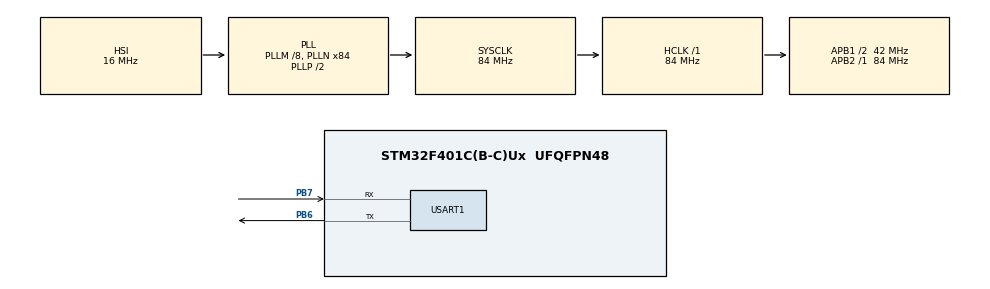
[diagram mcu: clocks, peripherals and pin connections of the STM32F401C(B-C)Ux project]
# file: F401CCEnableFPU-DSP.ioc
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Mcu.Family=STM32F4
Mcu.Name=STM32F401C(B-C)Ux
Mcu.Package=UFQFPN48
NVIC.PriorityGroup=NVIC_PRIORITYGROUP_4
PA13.Mode=Serial_Wire
PA13.Signal=SYS_JTMS-SWDIO
PA14.Mode=Serial_Wire
PA14.Signal=SYS_JTCK-SWCLK
PB6.Mode=Asynchronous
PB6.Signal=USART1_TX
PB7.Mode=Asynchronous
PB7.Signal=USART1_RX
ProjectManager.HeapSize=0x200
ProjectManager.StackSize=0x400
ProjectManager.TargetToolchain=SW4STM32
RCC.48MHZClocksFreq_Value=42000000
RCC.AHBFreq_Value=84000000
RCC.APB1CLKDivider=RCC_HCLK_DIV2
RCC.APB1Freq_Value=42000000
RCC.APB1TimFreq_Value=84000000
RCC.APB2Freq_Value=84000000
RCC.APB2TimFreq_Value=84000000
RCC.CortexFreq_Value=84000000
RCC.HCLKFreq_Value=84000000
RCC.HSE_VALUE=25000000
RCC.HSI_VALUE=16000000
RCC.LSE_VALUE=32768
RCC.PLLM=8
RCC.PLLN=84
RCC.SYSCLKFreq_VALUE=84000000
RCC.SYSCLKSource=RCC_SYSCLKSOURCE_PLLCLK
RCC.VCOOutputFreq_Value=168000000
USART1.VirtualMode=VM_ASYNC
board=custom

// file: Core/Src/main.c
/* USER CODE BEGIN Header */
/**
  ******************************************************************************
  * @file           : main.c
  * @brief          : Main program body
  ******************************************************************************
  * @attention
  *
  * Copyright (c) 2022 STMicroelectronics.
  * All rights reserved.
  *
  * This software is licensed under terms that can be found in the LICENSE file
  * in the root directory of this software component.
  * If no LICENSE file comes with this software, it is provided AS-IS.
  *
  ******************************************************************************
  */
/* USER CODE END Header */
#pragma clang diagnostic push
#pragma ide diagnostic ignored "EndlessLoop"
#include "main.h"
#include "usart.h"
#include "gpio.h"

/* USER CODE BEGIN Includes */
#include "use_dwt.h"
#include "math.h"

#ifdef ARM_MATH_CM4
#include "arm_math.h"
#endif
/* USER CODE END Includes */

void SystemClock_Config(void);

int main(void)
{

  /* MCU Configuration--------------------------------------------------------*/

  /* Reset of all peripherals, Initializes the Flash interface and the Systick. */
  HAL_Init();

  /* Configure the system clock */
  SystemClock_Config();

  /* Initialize all configured peripherals */
  MX_GPIO_Init();
  MX_USART1_UART_Init();
  /* USER CODE BEGIN 2 */
  DWT_Init();
  volatile float res;
  volatile float a = 0.5569f, b = 0.3772f;
  volatile uint32_t before, time;
  /* USER CODE END 2 */

  /* Infinite loop */
  /* USER CODE BEGIN WHILE */
  while (1)
  {
#ifdef _USING_ARM_MATH
      float f_tmp[] = {a, b, 0.0f};
      q31_t q_tmp[3];
      arm_float_to_q31(f_tmp, q_tmp, 2);
#endif
#ifdef _USING_IQ_MATH
      _iq aa = _IQ(a);
      _iq bb = _IQ(b);
      volatile _iq rr = 0;
#endif

      before = DWT_TS_GET();
      for (int i = 0; i < __MAX_LOOP_COUNT; ++i) {
#ifdef _ENABLE_TEST_FLOAT
#ifdef _USING_ARM_MATH
        arm_mult_q31(q_tmp, q_tmp + 1, q_tmp + 2, 1);
#elif _USING_IQ_MATH
        rr = _IQmpy(aa, bb);
#else
        res = a * b;
#endif
#endif

#ifdef _ENABLE_TEST_DSP
#ifndef _USING_FIX_POINT

#ifdef _USING_ARM_MATH
          res = arm_cos_f32(a) + arm_sin_f32(b);
#else
          res = cos(a) + sin(b);
#endif // _USING_ARM_MATH
#else
#ifdef _USING_ARM_MATH
          q_tmp[2] = arm_cos_q31(q_tmp[0]) + arm_sin_q31(q_tmp[1]);
#elif _USING_IQ_MATH
          rr = _IQcos(aa) + _IQcos(bb);
#endif // _USING_ARM_MATH

#endif // _USING_FIX_POINT
#endif // ENABLE_TEST_DSP
      }
      time = DWT_TS_GET() - before;
#ifdef _USING_ARM_MATH
      arm_q31_to_float(q_tmp + 2, f_tmp, 1);
      res = f_tmp[0];
#endif
#ifdef _USING_IQ_MATH
      rr = _IQtoF(rr);
#endif
      printf("Calc res = %f, CPU Cycle = %d\n", res, time);
      HAL_Delay(500);
    /* USER CODE END WHILE */

  }
}

void SystemClock_Config(void)
{
  RCC_OscInitTypeDef RCC_OscInitStruct = {0};
  RCC_ClkInitTypeDef RCC_ClkInitStruct = {0};

  /** Configure the main internal regulator output voltage
  */
  __HAL_RCC_PWR_CLK_ENABLE();
  __HAL_PWR_VOLTAGESCALING_CONFIG(PWR_REGULATOR_VOLTAGE_SCALE2);
  /** Initializes the RCC Oscillators according to the specified parameters
  * in the RCC_OscInitTypeDef structure.
  */
  RCC_OscInitStruct.OscillatorType = RCC_OSCILLATORTYPE_HSI;
  RCC_OscInitStruct.HSIState = RCC_HSI_ON;
  RCC_OscInitStruct.HSICalibrationValue = RCC_HSICALIBRATION_DEFAULT;
  RCC_OscInitStruct.PLL.PLLState = RCC_PLL_ON;
  RCC_OscInitStruct.PLL.PLLSource = RCC_PLLSOURCE_HSI;
  RCC_OscInitStruct.PLL.PLLM = 8;
  RCC_OscInitStruct.PLL.PLLN = 84;
  RCC_OscInitStruct.PLL.PLLP = RCC_PLLP_DIV2;
  RCC_OscInitStruct.PLL.PLLQ = 4;
  if (HAL_RCC_OscConfig(&RCC_OscInitStruct) != HAL_OK)
  {
    Error_Handler();
  }
  /** Initializes the CPU, AHB and APB buses clocks
  */
  RCC_ClkInitStruct.ClockType = RCC_CLOCKTYPE_HCLK|RCC_CLOCKTYPE_SYSCLK
                              |RCC_CLOCKTYPE_PCLK1|RCC_CLOCKTYPE_PCLK2;
  RCC_ClkInitStruct.SYSCLKSource = RCC_SYSCLKSOURCE_PLLCLK;
  RCC_ClkInitStruct.AHBCLKDivider = RCC_SYSCLK_DIV1;
  RCC_ClkInitStruct.APB1CLKDivider = RCC_HCLK_DIV2;
  RCC_ClkInitStruct.APB2CLKDivider = RCC_HCLK_DIV1;

  if (HAL_RCC_ClockConfig(&RCC_ClkInitStruct, FLASH_LATENCY_2) != HAL_OK)
  {
    Error_Handler();
  }
}

/* USER CODE BEGIN 4 */
void _putchar(char character)
{
    HAL_UART_Transmit(&huart1, (uint8_t *)&character, 1, 0xFF);
}
/* USER CODE END 4 */

void Error_Handler(void)
{
  /* USER CODE BEGIN Error_Handler_Debug */
  /* User can add his own implementation to report the HAL error return state */
#ifndef __DEBUG_MODE
  __disable_irq();
  while (1)
  {
  }
#endif
  /* USER CODE END Error_Handler_Debug */
}

#pragma clang diagnostic pop
